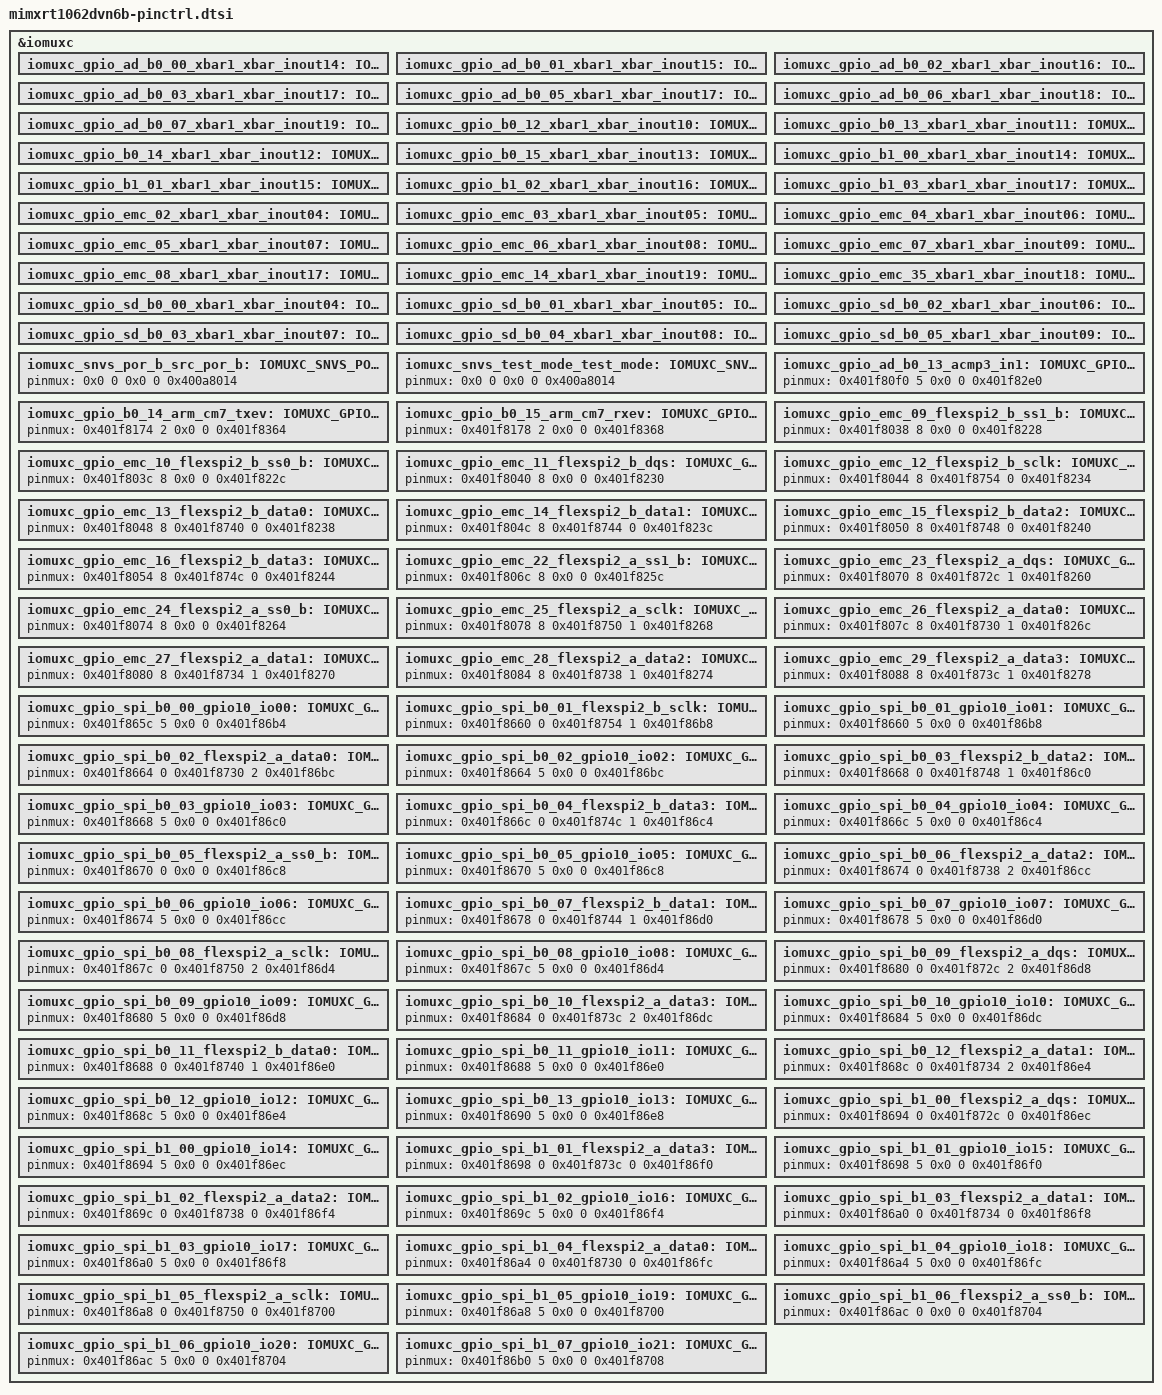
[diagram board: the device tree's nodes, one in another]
/*
 * Copyright 2023, NXP
 * SPDX-License-Identifier: Apache-2.0
 *
 * Note: File generated by imx_cfg_utils.py
 * from configuration data for MIMXRT1062DVN6B
 */

/*
 * Delta-deduplicated by dedup_pinctrl.py:
 * based on mimxrt1064dvj6a-pinctrl.dtsi with this part's differences applied
 * below (3 removed, 32 changed,
 * 60 added). Regenerate with dedup_pinctrl.py;
 * do not edit by hand.
 * target-hash: 304d2df1a5f7ddd6
 */

#include "mimxrt1064dvj6a-pinctrl.dtsi"

/delete-node/ &iomuxc_gpio_ad_b1_06_acmp3_in1;
/delete-node/ &iomuxc_gpio_b0_14_arm_txev;
/delete-node/ &iomuxc_gpio_b0_15_arm_rxev;
/delete-node/ &iomuxc_gpio_ad_b0_00_xbar1_xbar_inout14;
/delete-node/ &iomuxc_gpio_ad_b0_01_xbar1_xbar_inout15;
/delete-node/ &iomuxc_gpio_ad_b0_02_xbar1_xbar_inout16;
/delete-node/ &iomuxc_gpio_ad_b0_03_xbar1_xbar_inout17;
/delete-node/ &iomuxc_gpio_ad_b0_05_xbar1_xbar_inout17;
/delete-node/ &iomuxc_gpio_ad_b0_06_xbar1_xbar_inout18;
/delete-node/ &iomuxc_gpio_ad_b0_07_xbar1_xbar_inout19;
/delete-node/ &iomuxc_gpio_b0_12_xbar1_xbar_inout10;
/delete-node/ &iomuxc_gpio_b0_13_xbar1_xbar_inout11;
/delete-node/ &iomuxc_gpio_b0_14_xbar1_xbar_inout12;
/delete-node/ &iomuxc_gpio_b0_15_xbar1_xbar_inout13;
/delete-node/ &iomuxc_gpio_b1_00_xbar1_xbar_inout14;
/delete-node/ &iomuxc_gpio_b1_01_xbar1_xbar_inout15;
/delete-node/ &iomuxc_gpio_b1_02_xbar1_xbar_inout16;
/delete-node/ &iomuxc_gpio_b1_03_xbar1_xbar_inout17;
/delete-node/ &iomuxc_gpio_emc_02_xbar1_xbar_inout04;
/delete-node/ &iomuxc_gpio_emc_03_xbar1_xbar_inout05;
/delete-node/ &iomuxc_gpio_emc_04_xbar1_xbar_inout06;
/delete-node/ &iomuxc_gpio_emc_05_xbar1_xbar_inout07;
/delete-node/ &iomuxc_gpio_emc_06_xbar1_xbar_inout08;
/delete-node/ &iomuxc_gpio_emc_07_xbar1_xbar_inout09;
/delete-node/ &iomuxc_gpio_emc_08_xbar1_xbar_inout17;
/delete-node/ &iomuxc_gpio_emc_14_xbar1_xbar_inout19;
/delete-node/ &iomuxc_gpio_emc_35_xbar1_xbar_inout18;
/delete-node/ &iomuxc_gpio_sd_b0_00_xbar1_xbar_inout04;
/delete-node/ &iomuxc_gpio_sd_b0_01_xbar1_xbar_inout05;
/delete-node/ &iomuxc_gpio_sd_b0_02_xbar1_xbar_inout06;
/delete-node/ &iomuxc_gpio_sd_b0_03_xbar1_xbar_inout07;
/delete-node/ &iomuxc_gpio_sd_b0_04_xbar1_xbar_inout08;
/delete-node/ &iomuxc_gpio_sd_b0_05_xbar1_xbar_inout09;
/delete-node/ &iomuxc_snvs_por_b_src_por_b;
/delete-node/ &iomuxc_snvs_test_mode_test_mode;

&iomuxc {
	/omit-if-no-ref/ iomuxc_gpio_ad_b0_00_xbar1_xbar_inout14: IOMUXC_GPIO_AD_B0_00_XBAR1_XBAR_INOUT14 {
		pinmux = <0x401f80bc 1 0x401f8644 0 0x401f82ac>;
		gpr = <0x400ac018 0x1a 0x1>;
	};
	/omit-if-no-ref/ iomuxc_gpio_ad_b0_01_xbar1_xbar_inout15: IOMUXC_GPIO_AD_B0_01_XBAR1_XBAR_INOUT15 {
		pinmux = <0x401f80c0 1 0x401f8648 0 0x401f82b0>;
		gpr = <0x400ac018 0x1b 0x1>;
	};
	/omit-if-no-ref/ iomuxc_gpio_ad_b0_02_xbar1_xbar_inout16: IOMUXC_GPIO_AD_B0_02_XBAR1_XBAR_INOUT16 {
		pinmux = <0x401f80c4 1 0x401f864c 0 0x401f82b4>;
		gpr = <0x400ac018 0x1c 0x1>;
	};
	/omit-if-no-ref/ iomuxc_gpio_ad_b0_03_xbar1_xbar_inout17: IOMUXC_GPIO_AD_B0_03_XBAR1_XBAR_INOUT17 {
		pinmux = <0x401f80c8 1 0x401f862c 1 0x401f82b8>;
		gpr = <0x400ac018 0x1d 0x1>;
	};
	/omit-if-no-ref/ iomuxc_gpio_ad_b0_05_xbar1_xbar_inout17: IOMUXC_GPIO_AD_B0_05_XBAR1_XBAR_INOUT17 {
		pinmux = <0x401f80d0 6 0x401f862c 2 0x401f82c0>;
		gpr = <0x400ac018 0x1d 0x1>;
	};
	/omit-if-no-ref/ iomuxc_gpio_ad_b0_06_xbar1_xbar_inout18: IOMUXC_GPIO_AD_B0_06_XBAR1_XBAR_INOUT18 {
		pinmux = <0x401f80d4 6 0x401f8630 1 0x401f82c4>;
		gpr = <0x400ac018 0x1e 0x1>;
	};
	/omit-if-no-ref/ iomuxc_gpio_ad_b0_07_xbar1_xbar_inout19: IOMUXC_GPIO_AD_B0_07_XBAR1_XBAR_INOUT19 {
		pinmux = <0x401f80d8 6 0x401f8654 1 0x401f82c8>;
		gpr = <0x400ac018 0x1f 0x1>;
	};
	/omit-if-no-ref/ iomuxc_gpio_b0_12_xbar1_xbar_inout10: IOMUXC_GPIO_B0_12_XBAR1_XBAR_INOUT10 {
		pinmux = <0x401f816c 1 0x0 0 0x401f835c>;
		gpr = <0x400ac018 0x16 0x1>;
	};
	/omit-if-no-ref/ iomuxc_gpio_b0_13_xbar1_xbar_inout11: IOMUXC_GPIO_B0_13_XBAR1_XBAR_INOUT11 {
		pinmux = <0x401f8170 1 0x0 0 0x401f8360>;
		gpr = <0x400ac018 0x17 0x1>;
	};
	/omit-if-no-ref/ iomuxc_gpio_b0_14_xbar1_xbar_inout12: IOMUXC_GPIO_B0_14_XBAR1_XBAR_INOUT12 {
		pinmux = <0x401f8174 1 0x0 0 0x401f8364>;
		gpr = <0x400ac018 0x18 0x1>;
	};
	/omit-if-no-ref/ iomuxc_gpio_b0_15_xbar1_xbar_inout13: IOMUXC_GPIO_B0_15_XBAR1_XBAR_INOUT13 {
		pinmux = <0x401f8178 1 0x0 0 0x401f8368>;
		gpr = <0x400ac018 0x19 0x1>;
	};
	/omit-if-no-ref/ iomuxc_gpio_b1_00_xbar1_xbar_inout14: IOMUXC_GPIO_B1_00_XBAR1_XBAR_INOUT14 {
		pinmux = <0x401f817c 1 0x401f8644 1 0x401f836c>;
		gpr = <0x400ac018 0x1a 0x1>;
	};
	/omit-if-no-ref/ iomuxc_gpio_b1_01_xbar1_xbar_inout15: IOMUXC_GPIO_B1_01_XBAR1_XBAR_INOUT15 {
		pinmux = <0x401f8180 1 0x401f8648 1 0x401f8370>;
		gpr = <0x400ac018 0x1b 0x1>;
	};
	/omit-if-no-ref/ iomuxc_gpio_b1_02_xbar1_xbar_inout16: IOMUXC_GPIO_B1_02_XBAR1_XBAR_INOUT16 {
		pinmux = <0x401f8184 1 0x401f864c 1 0x401f8374>;
		gpr = <0x400ac018 0x1c 0x1>;
	};
	/omit-if-no-ref/ iomuxc_gpio_b1_03_xbar1_xbar_inout17: IOMUXC_GPIO_B1_03_XBAR1_XBAR_INOUT17 {
		pinmux = <0x401f8188 1 0x401f862c 3 0x401f8378>;
		gpr = <0x400ac018 0x1d 0x1>;
	};
	/omit-if-no-ref/ iomuxc_gpio_emc_02_xbar1_xbar_inout04: IOMUXC_GPIO_EMC_02_XBAR1_XBAR_INOUT04 {
		pinmux = <0x401f801c 3 0x401f8614 0 0x401f820c>;
		gpr = <0x400ac018 0x10 0x1>;
	};
	/omit-if-no-ref/ iomuxc_gpio_emc_03_xbar1_xbar_inout05: IOMUXC_GPIO_EMC_03_XBAR1_XBAR_INOUT05 {
		pinmux = <0x401f8020 3 0x401f8618 0 0x401f8210>;
		gpr = <0x400ac018 0x11 0x1>;
	};
	/omit-if-no-ref/ iomuxc_gpio_emc_04_xbar1_xbar_inout06: IOMUXC_GPIO_EMC_04_XBAR1_XBAR_INOUT06 {
		pinmux = <0x401f8024 3 0x401f861c 0 0x401f8214>;
		gpr = <0x400ac018 0x12 0x1>;
	};
	/omit-if-no-ref/ iomuxc_gpio_emc_05_xbar1_xbar_inout07: IOMUXC_GPIO_EMC_05_XBAR1_XBAR_INOUT07 {
		pinmux = <0x401f8028 3 0x401f8620 0 0x401f8218>;
		gpr = <0x400ac018 0x13 0x1>;
	};
	/omit-if-no-ref/ iomuxc_gpio_emc_06_xbar1_xbar_inout08: IOMUXC_GPIO_EMC_06_XBAR1_XBAR_INOUT08 {
		pinmux = <0x401f802c 3 0x401f8624 0 0x401f821c>;
		gpr = <0x400ac018 0x14 0x1>;
	};
	/omit-if-no-ref/ iomuxc_gpio_emc_07_xbar1_xbar_inout09: IOMUXC_GPIO_EMC_07_XBAR1_XBAR_INOUT09 {
		pinmux = <0x401f8030 3 0x401f8628 0 0x401f8220>;
		gpr = <0x400ac018 0x15 0x1>;
	};
	/omit-if-no-ref/ iomuxc_gpio_emc_08_xbar1_xbar_inout17: IOMUXC_GPIO_EMC_08_XBAR1_XBAR_INOUT17 {
		pinmux = <0x401f8034 3 0x401f862c 0 0x401f8224>;
		gpr = <0x400ac018 0x1d 0x1>;
	};
	/omit-if-no-ref/ iomuxc_gpio_emc_14_xbar1_xbar_inout19: IOMUXC_GPIO_EMC_14_XBAR1_XBAR_INOUT19 {
		pinmux = <0x401f804c 1 0x401f8654 0 0x401f823c>;
		gpr = <0x400ac018 0x1f 0x1>;
	};
	/omit-if-no-ref/ iomuxc_gpio_emc_35_xbar1_xbar_inout18: IOMUXC_GPIO_EMC_35_XBAR1_XBAR_INOUT18 {
		pinmux = <0x401f80a0 1 0x401f8630 0 0x401f8290>;
		gpr = <0x400ac018 0x1e 0x1>;
	};
	/omit-if-no-ref/ iomuxc_gpio_sd_b0_00_xbar1_xbar_inout04: IOMUXC_GPIO_SD_B0_00_XBAR1_XBAR_INOUT04 {
		pinmux = <0x401f81bc 3 0x401f8614 1 0x401f83ac>;
		gpr = <0x400ac018 0x10 0x1>;
	};
	/omit-if-no-ref/ iomuxc_gpio_sd_b0_01_xbar1_xbar_inout05: IOMUXC_GPIO_SD_B0_01_XBAR1_XBAR_INOUT05 {
		pinmux = <0x401f81c0 3 0x401f8618 1 0x401f83b0>;
		gpr = <0x400ac018 0x11 0x1>;
	};
	/omit-if-no-ref/ iomuxc_gpio_sd_b0_02_xbar1_xbar_inout06: IOMUXC_GPIO_SD_B0_02_XBAR1_XBAR_INOUT06 {
		pinmux = <0x401f81c4 3 0x401f861c 1 0x401f83b4>;
		gpr = <0x400ac018 0x12 0x1>;
	};
	/omit-if-no-ref/ iomuxc_gpio_sd_b0_03_xbar1_xbar_inout07: IOMUXC_GPIO_SD_B0_03_XBAR1_XBAR_INOUT07 {
		pinmux = <0x401f81c8 3 0x401f8620 1 0x401f83b8>;
		gpr = <0x400ac018 0x13 0x1>;
	};
	/omit-if-no-ref/ iomuxc_gpio_sd_b0_04_xbar1_xbar_inout08: IOMUXC_GPIO_SD_B0_04_XBAR1_XBAR_INOUT08 {
		pinmux = <0x401f81cc 3 0x401f8624 1 0x401f83bc>;
		gpr = <0x400ac018 0x14 0x1>;
	};
	/omit-if-no-ref/ iomuxc_gpio_sd_b0_05_xbar1_xbar_inout09: IOMUXC_GPIO_SD_B0_05_XBAR1_XBAR_INOUT09 {
		pinmux = <0x401f81d0 3 0x401f8628 1 0x401f83c0>;
		gpr = <0x400ac018 0x15 0x1>;
	};
	/omit-if-no-ref/ iomuxc_snvs_por_b_src_por_b: IOMUXC_SNVS_POR_B_SRC_POR_B {
		pinmux = <0x0 0 0x0 0 0x400a8014>;
	};
	/omit-if-no-ref/ iomuxc_snvs_test_mode_test_mode: IOMUXC_SNVS_TEST_MODE_TEST_MODE {
		pinmux = <0x0 0 0x0 0 0x400a8014>;
	};
	/omit-if-no-ref/ iomuxc_gpio_ad_b0_13_acmp3_in1: IOMUXC_GPIO_AD_B0_13_ACMP3_IN1 {
		pinmux = <0x401f80f0 5 0x0 0 0x401f82e0>;
	};
	/omit-if-no-ref/ iomuxc_gpio_b0_14_arm_cm7_txev: IOMUXC_GPIO_B0_14_ARM_CM7_TXEV {
		pinmux = <0x401f8174 2 0x0 0 0x401f8364>;
	};
	/omit-if-no-ref/ iomuxc_gpio_b0_15_arm_cm7_rxev: IOMUXC_GPIO_B0_15_ARM_CM7_RXEV {
		pinmux = <0x401f8178 2 0x0 0 0x401f8368>;
	};
	/omit-if-no-ref/ iomuxc_gpio_emc_09_flexspi2_b_ss1_b: IOMUXC_GPIO_EMC_09_FLEXSPI2_B_SS1_B {
		pinmux = <0x401f8038 8 0x0 0 0x401f8228>;
	};
	/omit-if-no-ref/ iomuxc_gpio_emc_10_flexspi2_b_ss0_b: IOMUXC_GPIO_EMC_10_FLEXSPI2_B_SS0_B {
		pinmux = <0x401f803c 8 0x0 0 0x401f822c>;
	};
	/omit-if-no-ref/ iomuxc_gpio_emc_11_flexspi2_b_dqs: IOMUXC_GPIO_EMC_11_FLEXSPI2_B_DQS {
		pinmux = <0x401f8040 8 0x0 0 0x401f8230>;
	};
	/omit-if-no-ref/ iomuxc_gpio_emc_12_flexspi2_b_sclk: IOMUXC_GPIO_EMC_12_FLEXSPI2_B_SCLK {
		pinmux = <0x401f8044 8 0x401f8754 0 0x401f8234>;
	};
	/omit-if-no-ref/ iomuxc_gpio_emc_13_flexspi2_b_data0: IOMUXC_GPIO_EMC_13_FLEXSPI2_B_DATA0 {
		pinmux = <0x401f8048 8 0x401f8740 0 0x401f8238>;
	};
	/omit-if-no-ref/ iomuxc_gpio_emc_14_flexspi2_b_data1: IOMUXC_GPIO_EMC_14_FLEXSPI2_B_DATA1 {
		pinmux = <0x401f804c 8 0x401f8744 0 0x401f823c>;
	};
	/omit-if-no-ref/ iomuxc_gpio_emc_15_flexspi2_b_data2: IOMUXC_GPIO_EMC_15_FLEXSPI2_B_DATA2 {
		pinmux = <0x401f8050 8 0x401f8748 0 0x401f8240>;
	};
	/omit-if-no-ref/ iomuxc_gpio_emc_16_flexspi2_b_data3: IOMUXC_GPIO_EMC_16_FLEXSPI2_B_DATA3 {
		pinmux = <0x401f8054 8 0x401f874c 0 0x401f8244>;
	};
	/omit-if-no-ref/ iomuxc_gpio_emc_22_flexspi2_a_ss1_b: IOMUXC_GPIO_EMC_22_FLEXSPI2_A_SS1_B {
		pinmux = <0x401f806c 8 0x0 0 0x401f825c>;
	};
	/omit-if-no-ref/ iomuxc_gpio_emc_23_flexspi2_a_dqs: IOMUXC_GPIO_EMC_23_FLEXSPI2_A_DQS {
		pinmux = <0x401f8070 8 0x401f872c 1 0x401f8260>;
	};
	/omit-if-no-ref/ iomuxc_gpio_emc_24_flexspi2_a_ss0_b: IOMUXC_GPIO_EMC_24_FLEXSPI2_A_SS0_B {
		pinmux = <0x401f8074 8 0x0 0 0x401f8264>;
	};
	/omit-if-no-ref/ iomuxc_gpio_emc_25_flexspi2_a_sclk: IOMUXC_GPIO_EMC_25_FLEXSPI2_A_SCLK {
		pinmux = <0x401f8078 8 0x401f8750 1 0x401f8268>;
	};
	/omit-if-no-ref/ iomuxc_gpio_emc_26_flexspi2_a_data0: IOMUXC_GPIO_EMC_26_FLEXSPI2_A_DATA0 {
		pinmux = <0x401f807c 8 0x401f8730 1 0x401f826c>;
	};
	/omit-if-no-ref/ iomuxc_gpio_emc_27_flexspi2_a_data1: IOMUXC_GPIO_EMC_27_FLEXSPI2_A_DATA1 {
		pinmux = <0x401f8080 8 0x401f8734 1 0x401f8270>;
	};
	/omit-if-no-ref/ iomuxc_gpio_emc_28_flexspi2_a_data2: IOMUXC_GPIO_EMC_28_FLEXSPI2_A_DATA2 {
		pinmux = <0x401f8084 8 0x401f8738 1 0x401f8274>;
	};
	/omit-if-no-ref/ iomuxc_gpio_emc_29_flexspi2_a_data3: IOMUXC_GPIO_EMC_29_FLEXSPI2_A_DATA3 {
		pinmux = <0x401f8088 8 0x401f873c 1 0x401f8278>;
	};
	/omit-if-no-ref/ iomuxc_gpio_spi_b0_00_gpio10_io00: IOMUXC_GPIO_SPI_B0_00_GPIO10_IO00 {
		pinmux = <0x401f865c 5 0x0 0 0x401f86b4>;
	};
	/omit-if-no-ref/ iomuxc_gpio_spi_b0_01_flexspi2_b_sclk: IOMUXC_GPIO_SPI_B0_01_FLEXSPI2_B_SCLK {
		pinmux = <0x401f8660 0 0x401f8754 1 0x401f86b8>;
	};
	/omit-if-no-ref/ iomuxc_gpio_spi_b0_01_gpio10_io01: IOMUXC_GPIO_SPI_B0_01_GPIO10_IO01 {
		pinmux = <0x401f8660 5 0x0 0 0x401f86b8>;
	};
	/omit-if-no-ref/ iomuxc_gpio_spi_b0_02_flexspi2_a_data0: IOMUXC_GPIO_SPI_B0_02_FLEXSPI2_A_DATA0 {
		pinmux = <0x401f8664 0 0x401f8730 2 0x401f86bc>;
	};
	/omit-if-no-ref/ iomuxc_gpio_spi_b0_02_gpio10_io02: IOMUXC_GPIO_SPI_B0_02_GPIO10_IO02 {
		pinmux = <0x401f8664 5 0x0 0 0x401f86bc>;
	};
	/omit-if-no-ref/ iomuxc_gpio_spi_b0_03_flexspi2_b_data2: IOMUXC_GPIO_SPI_B0_03_FLEXSPI2_B_DATA2 {
		pinmux = <0x401f8668 0 0x401f8748 1 0x401f86c0>;
	};
	/omit-if-no-ref/ iomuxc_gpio_spi_b0_03_gpio10_io03: IOMUXC_GPIO_SPI_B0_03_GPIO10_IO03 {
		pinmux = <0x401f8668 5 0x0 0 0x401f86c0>;
	};
	/omit-if-no-ref/ iomuxc_gpio_spi_b0_04_flexspi2_b_data3: IOMUXC_GPIO_SPI_B0_04_FLEXSPI2_B_DATA3 {
		pinmux = <0x401f866c 0 0x401f874c 1 0x401f86c4>;
	};
	/omit-if-no-ref/ iomuxc_gpio_spi_b0_04_gpio10_io04: IOMUXC_GPIO_SPI_B0_04_GPIO10_IO04 {
		pinmux = <0x401f866c 5 0x0 0 0x401f86c4>;
	};
	/omit-if-no-ref/ iomuxc_gpio_spi_b0_05_flexspi2_a_ss0_b: IOMUXC_GPIO_SPI_B0_05_FLEXSPI2_A_SS0_B {
		pinmux = <0x401f8670 0 0x0 0 0x401f86c8>;
	};
	/omit-if-no-ref/ iomuxc_gpio_spi_b0_05_gpio10_io05: IOMUXC_GPIO_SPI_B0_05_GPIO10_IO05 {
		pinmux = <0x401f8670 5 0x0 0 0x401f86c8>;
	};
	/omit-if-no-ref/ iomuxc_gpio_spi_b0_06_flexspi2_a_data2: IOMUXC_GPIO_SPI_B0_06_FLEXSPI2_A_DATA2 {
		pinmux = <0x401f8674 0 0x401f8738 2 0x401f86cc>;
	};
	/omit-if-no-ref/ iomuxc_gpio_spi_b0_06_gpio10_io06: IOMUXC_GPIO_SPI_B0_06_GPIO10_IO06 {
		pinmux = <0x401f8674 5 0x0 0 0x401f86cc>;
	};
	/omit-if-no-ref/ iomuxc_gpio_spi_b0_07_flexspi2_b_data1: IOMUXC_GPIO_SPI_B0_07_FLEXSPI2_B_DATA1 {
		pinmux = <0x401f8678 0 0x401f8744 1 0x401f86d0>;
	};
	/omit-if-no-ref/ iomuxc_gpio_spi_b0_07_gpio10_io07: IOMUXC_GPIO_SPI_B0_07_GPIO10_IO07 {
		pinmux = <0x401f8678 5 0x0 0 0x401f86d0>;
	};
	/omit-if-no-ref/ iomuxc_gpio_spi_b0_08_flexspi2_a_sclk: IOMUXC_GPIO_SPI_B0_08_FLEXSPI2_A_SCLK {
		pinmux = <0x401f867c 0 0x401f8750 2 0x401f86d4>;
	};
	/omit-if-no-ref/ iomuxc_gpio_spi_b0_08_gpio10_io08: IOMUXC_GPIO_SPI_B0_08_GPIO10_IO08 {
		pinmux = <0x401f867c 5 0x0 0 0x401f86d4>;
	};
	/omit-if-no-ref/ iomuxc_gpio_spi_b0_09_flexspi2_a_dqs: IOMUXC_GPIO_SPI_B0_09_FLEXSPI2_A_DQS {
		pinmux = <0x401f8680 0 0x401f872c 2 0x401f86d8>;
	};
	/omit-if-no-ref/ iomuxc_gpio_spi_b0_09_gpio10_io09: IOMUXC_GPIO_SPI_B0_09_GPIO10_IO09 {
		pinmux = <0x401f8680 5 0x0 0 0x401f86d8>;
	};
	/omit-if-no-ref/ iomuxc_gpio_spi_b0_10_flexspi2_a_data3: IOMUXC_GPIO_SPI_B0_10_FLEXSPI2_A_DATA3 {
		pinmux = <0x401f8684 0 0x401f873c 2 0x401f86dc>;
	};
	/omit-if-no-ref/ iomuxc_gpio_spi_b0_10_gpio10_io10: IOMUXC_GPIO_SPI_B0_10_GPIO10_IO10 {
		pinmux = <0x401f8684 5 0x0 0 0x401f86dc>;
	};
	/omit-if-no-ref/ iomuxc_gpio_spi_b0_11_flexspi2_b_data0: IOMUXC_GPIO_SPI_B0_11_FLEXSPI2_B_DATA0 {
		pinmux = <0x401f8688 0 0x401f8740 1 0x401f86e0>;
	};
	/omit-if-no-ref/ iomuxc_gpio_spi_b0_11_gpio10_io11: IOMUXC_GPIO_SPI_B0_11_GPIO10_IO11 {
		pinmux = <0x401f8688 5 0x0 0 0x401f86e0>;
	};
	/omit-if-no-ref/ iomuxc_gpio_spi_b0_12_flexspi2_a_data1: IOMUXC_GPIO_SPI_B0_12_FLEXSPI2_A_DATA1 {
		pinmux = <0x401f868c 0 0x401f8734 2 0x401f86e4>;
	};
	/omit-if-no-ref/ iomuxc_gpio_spi_b0_12_gpio10_io12: IOMUXC_GPIO_SPI_B0_12_GPIO10_IO12 {
		pinmux = <0x401f868c 5 0x0 0 0x401f86e4>;
	};
	/omit-if-no-ref/ iomuxc_gpio_spi_b0_13_gpio10_io13: IOMUXC_GPIO_SPI_B0_13_GPIO10_IO13 {
		pinmux = <0x401f8690 5 0x0 0 0x401f86e8>;
	};
	/omit-if-no-ref/ iomuxc_gpio_spi_b1_00_flexspi2_a_dqs: IOMUXC_GPIO_SPI_B1_00_FLEXSPI2_A_DQS {
		pinmux = <0x401f8694 0 0x401f872c 0 0x401f86ec>;
	};
	/omit-if-no-ref/ iomuxc_gpio_spi_b1_00_gpio10_io14: IOMUXC_GPIO_SPI_B1_00_GPIO10_IO14 {
		pinmux = <0x401f8694 5 0x0 0 0x401f86ec>;
	};
	/omit-if-no-ref/ iomuxc_gpio_spi_b1_01_flexspi2_a_data3: IOMUXC_GPIO_SPI_B1_01_FLEXSPI2_A_DATA3 {
		pinmux = <0x401f8698 0 0x401f873c 0 0x401f86f0>;
	};
	/omit-if-no-ref/ iomuxc_gpio_spi_b1_01_gpio10_io15: IOMUXC_GPIO_SPI_B1_01_GPIO10_IO15 {
		pinmux = <0x401f8698 5 0x0 0 0x401f86f0>;
	};
	/omit-if-no-ref/ iomuxc_gpio_spi_b1_02_flexspi2_a_data2: IOMUXC_GPIO_SPI_B1_02_FLEXSPI2_A_DATA2 {
		pinmux = <0x401f869c 0 0x401f8738 0 0x401f86f4>;
	};
	/omit-if-no-ref/ iomuxc_gpio_spi_b1_02_gpio10_io16: IOMUXC_GPIO_SPI_B1_02_GPIO10_IO16 {
		pinmux = <0x401f869c 5 0x0 0 0x401f86f4>;
	};
	/omit-if-no-ref/ iomuxc_gpio_spi_b1_03_flexspi2_a_data1: IOMUXC_GPIO_SPI_B1_03_FLEXSPI2_A_DATA1 {
		pinmux = <0x401f86a0 0 0x401f8734 0 0x401f86f8>;
	};
	/omit-if-no-ref/ iomuxc_gpio_spi_b1_03_gpio10_io17: IOMUXC_GPIO_SPI_B1_03_GPIO10_IO17 {
		pinmux = <0x401f86a0 5 0x0 0 0x401f86f8>;
	};
	/omit-if-no-ref/ iomuxc_gpio_spi_b1_04_flexspi2_a_data0: IOMUXC_GPIO_SPI_B1_04_FLEXSPI2_A_DATA0 {
		pinmux = <0x401f86a4 0 0x401f8730 0 0x401f86fc>;
	};
	/omit-if-no-ref/ iomuxc_gpio_spi_b1_04_gpio10_io18: IOMUXC_GPIO_SPI_B1_04_GPIO10_IO18 {
		pinmux = <0x401f86a4 5 0x0 0 0x401f86fc>;
	};
	/omit-if-no-ref/ iomuxc_gpio_spi_b1_05_flexspi2_a_sclk: IOMUXC_GPIO_SPI_B1_05_FLEXSPI2_A_SCLK {
		pinmux = <0x401f86a8 0 0x401f8750 0 0x401f8700>;
	};
	/omit-if-no-ref/ iomuxc_gpio_spi_b1_05_gpio10_io19: IOMUXC_GPIO_SPI_B1_05_GPIO10_IO19 {
		pinmux = <0x401f86a8 5 0x0 0 0x401f8700>;
	};
	/omit-if-no-ref/ iomuxc_gpio_spi_b1_06_flexspi2_a_ss0_b: IOMUXC_GPIO_SPI_B1_06_FLEXSPI2_A_SS0_B {
		pinmux = <0x401f86ac 0 0x0 0 0x401f8704>;
	};
	/omit-if-no-ref/ iomuxc_gpio_spi_b1_06_gpio10_io20: IOMUXC_GPIO_SPI_B1_06_GPIO10_IO20 {
		pinmux = <0x401f86ac 5 0x0 0 0x401f8704>;
	};
	/omit-if-no-ref/ iomuxc_gpio_spi_b1_07_gpio10_io21: IOMUXC_GPIO_SPI_B1_07_GPIO10_IO21 {
		pinmux = <0x401f86b0 5 0x0 0 0x401f8708>;
	};
};
